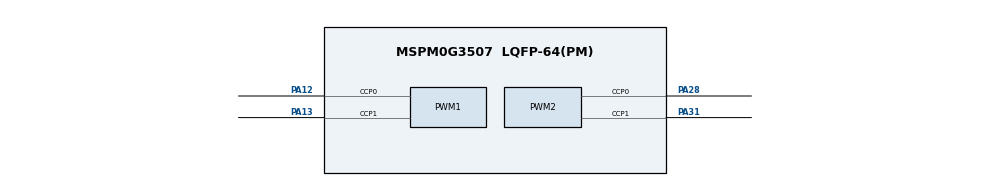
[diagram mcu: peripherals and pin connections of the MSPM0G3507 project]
/**
 * MSPM0G3507 自动循迹小车 - SysConfig 引脚配置
 * Automatic Line-Following Car - Pin Configuration
 *
 * 参考项目: C:\Users\sznnn\Desktop\car
 * 硬件: 8路GPIO数字灰度传感器 + AT8236双路电机驱动
 *
 * @cliArgs --device "MSPM0G3507" --package "LQFP-64(PM)" --product "mspm0_sdk@2.10.00.04"
 * @versions {"tool":"1.22.0"}
 */

const PWM    = scripting.addModule("/ti/driverlib/PWM", {}, false);
const PWM1   = PWM.addInstance();
const PWM2   = PWM.addInstance();
const GPIO   = scripting.addModule("/ti/driverlib/GPIO", {}, false);
const GPIO1  = GPIO.addInstance();
const GPIO2  = GPIO.addInstance();
const GPIO3  = GPIO.addInstance();
const GPIO4  = GPIO.addInstance();
const SYSCTL = scripting.addModule("/ti/driverlib/SYSCTL");

/* ================================================================
 * 左后轮电机 / Left Rear Motor
 * AT8236 AIN1/AIN2 → PA12/PA13
 * TIMG0 双通道PWM
 * ================================================================ */
PWM1.$name                      = "PWM_LEFT";
PWM1.clockDivider               = 8;
PWM1.clockPrescale              = 40;
PWM1.peripheral.$assign         = "TIMG0";
PWM1.peripheral.ccp0Pin.$assign = "PA12";
PWM1.peripheral.ccp1Pin.$assign = "PA13";

/* ================================================================
 * 右后轮电机 / Right Rear Motor
 * AT8236 BIN1/BIN2 → PA28/PA31
 * TIMG7 双通道PWM
 * ================================================================ */
PWM2.$name                      = "PWM_RIGHT";
PWM2.clockDivider               = 8;
PWM2.clockPrescale              = 40;
PWM2.peripheral.$assign         = "TIMG7";
PWM2.peripheral.ccp0Pin.$assign = "PA28";
PWM2.peripheral.ccp1Pin.$assign = "PA31";

/* ================================================================
 * 8路灰度传感器 (X1~X8)
 * 8-way digital grayscale sensor inputs (X1~X8)
 *
 * 传感器类型：数字输出（带阈值比较器）
 * 黑线=高电平(1), 白底=低电平(0)
 *
 * Sensor type: digital output with comparator
 * Black line = HIGH(1), White ground = LOW(0)
 *
 * X1 = PA15, X2 = PA17, X3 = PA22, X4 = PA24
 * X5 = PA25, X6 = PA26, X7 = PA27, X8 = PB20
 * ================================================================ */
GPIO1.$name                              = "GPIO_LINE";
GPIO1.associatedPins.create(8);
GPIO1.associatedPins[0].$name            = "LINE_X1";
GPIO1.associatedPins[0].assignedPort     = "PORTA";
GPIO1.associatedPins[0].assignedPin      = "15";
GPIO1.associatedPins[0].direction        = "INPUT";
GPIO1.associatedPins[1].$name            = "LINE_X2";
GPIO1.associatedPins[1].assignedPort     = "PORTA";
GPIO1.associatedPins[1].assignedPin      = "17";
GPIO1.associatedPins[1].direction        = "INPUT";
GPIO1.associatedPins[2].$name            = "LINE_X3";
GPIO1.associatedPins[2].assignedPort     = "PORTA";
GPIO1.associatedPins[2].assignedPin      = "22";
GPIO1.associatedPins[2].direction        = "INPUT";
GPIO1.associatedPins[3].$name            = "LINE_X4";
GPIO1.associatedPins[3].assignedPort     = "PORTA";
GPIO1.associatedPins[3].assignedPin      = "24";
GPIO1.associatedPins[3].direction        = "INPUT";
GPIO1.associatedPins[4].$name            = "LINE_X5";
GPIO1.associatedPins[4].assignedPort     = "PORTA";
GPIO1.associatedPins[4].assignedPin      = "25";
GPIO1.associatedPins[4].direction        = "INPUT";
GPIO1.associatedPins[5].$name            = "LINE_X6";
GPIO1.associatedPins[5].assignedPort     = "PORTA";
GPIO1.associatedPins[5].assignedPin      = "26";
GPIO1.associatedPins[5].direction        = "INPUT";
GPIO1.associatedPins[6].$name            = "LINE_X7";
GPIO1.associatedPins[6].assignedPort     = "PORTA";
GPIO1.associatedPins[6].assignedPin      = "27";
GPIO1.associatedPins[6].direction        = "INPUT";
GPIO1.associatedPins[7].$name            = "LINE_X8";
GPIO1.associatedPins[7].assignedPort     = "PORTB";
GPIO1.associatedPins[7].assignedPin      = "20";
GPIO1.associatedPins[7].direction        = "INPUT";

/* ================================================================
 * Debug接口 / Debug Interface
 * ================================================================ */
const Board = scripting.addModule("/ti/driverlib/Board", {}, false);
Board.peripheral.$suggestSolution          = "DEBUGSS";
Board.peripheral.swclkPin.$suggestSolution = "PA20";
Board.peripheral.swdioPin.$suggestSolution = "PA19";

/* ================================================================
 * 时钟配置 / Clock Configuration
 * 使用默认32MHz内部时钟
 * ================================================================ */
SYSCTL.forceDefaultClkConfig = true;
